# STM32L562 register map
File version: 1.1
Registers are 32-bit, read-write, reset 0x0 unless marked. A register's access mark holds for its fields unless they carry their own. Offsets are from the block's base; lines under a group give offsets from that group; [hi:lo] are bit positions; {n}, {i} and the like mark numbered series; 'fields as' and 'values as' point back to an identical list; <NAME> marks a mode.

## Memory map
0x40020800 DMAMUX1 size 0x400 — Direct memory access Multiplexer

## Interrupts
27 DMAMUX1_OVR (DMAMUX1) — DMAMUX overrun interrupt
28 DMAMUX1_OVR_S (DMAMUX1) — DMAMUX1 secure overRun interrupt

## DMAMUX1 — Direct memory access Multiplexer
Base 0x40020800
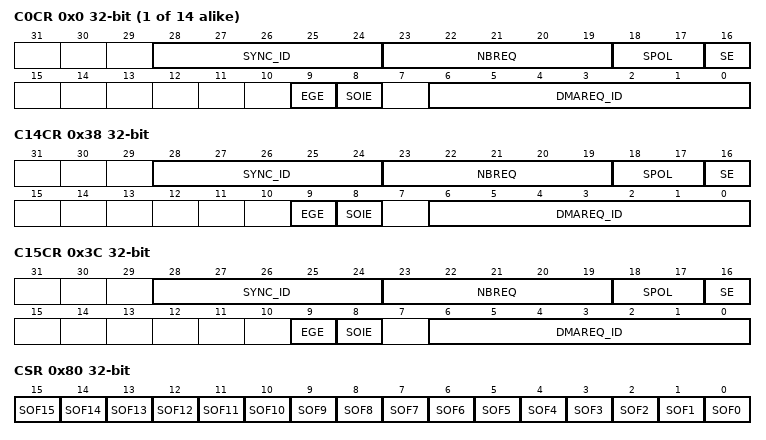
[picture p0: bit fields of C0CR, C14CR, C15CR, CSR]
{0x0+4i} C{i}CR (i=0..13) — DMA Multiplexer Channel {i} Control register
  [28:24] SYNC_ID
  [23:19] NBREQ — Nb request
  [18:17] SPOL — Sync polarity
  [16] SE — Synchronization enable
  [9] EGE — Event Generation Enable
  [8] SOIE — Synchronization Overrun Interrupt Enable
  [6:0] DMAREQ_ID — DMA Request ID
0x38 C14CR — DMA Multiplexer Channel 10 Control register
  [28:24] SYNC_ID — Synchronization identification
  [23:19] NBREQ — Number of DMA requests minus 1 to forward
  [18:17] SPOL — Synchronization polarity
  [16] SE — Synchronization enable
  [9] EGE — Event generation enable
  [8] SOIE — Synchronization overrun interrupt enable
  [6:0] DMAREQ_ID — DMA request identification
0x3C C15CR — DMA Multiplexer Channel 10 Control register
  fields as C14CR
0x80 CSR — DMA Multiplexer Channel Status register
  [15] SOF15 — Synchronization Overrun Flag 13
  [14] SOF14 — Synchronization Overrun Flag 13
  [n] SOF{n} (n=0..13) — Synchronization Overrun Flag {n}
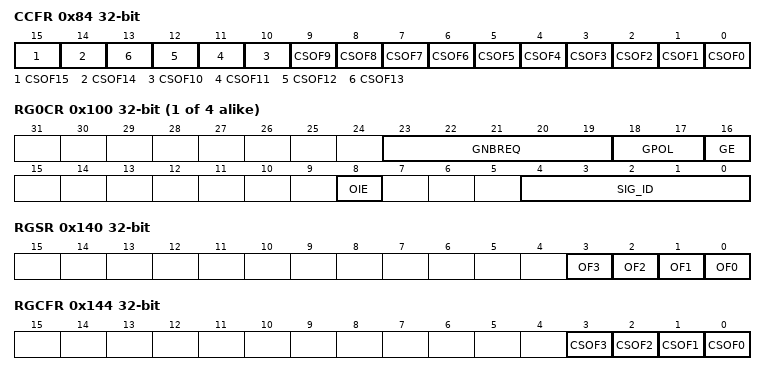
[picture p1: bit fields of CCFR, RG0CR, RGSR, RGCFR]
0x84 CCFR — DMA Channel Clear Flag Register
  [15] CSOF15 — Synchronization Clear Overrun Flag 13
  [14] CSOF14 — Synchronization Clear Overrun Flag 13
  [n] CSOF{n} (n=0..13) — Synchronization Clear Overrun Flag {n}
{0x100+4i} RG{i}CR (i=0..3) — DMA Request Generator {i} Control Register
  [23:19] GNBREQ — Number of Request
  [18:17] GPOL — Generation Polarity
  [16] GE — Generation Enable
  [8] OIE — Overrun Interrupt Enable
  [4:0] SIG_ID — Signal ID
0x140 RGSR ro — DMA Request Generator Status Register
  [n] OF{n} (n=0..3) — Generator Overrun Flag {n}
0x144 RGCFR — DMA Request Generator Clear Flag Register
  [n] CSOF{n} (n=0..3) — Generator Clear Overrun Flag {n}
